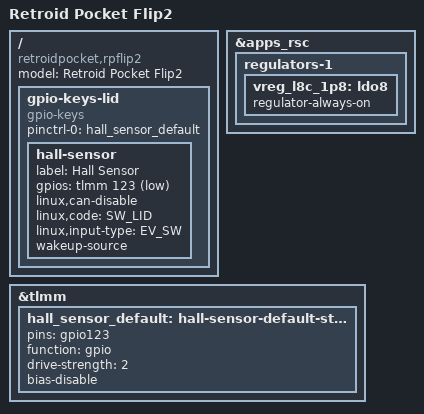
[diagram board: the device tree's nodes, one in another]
// SPDX-License-Identifier: GPL-2.0
/*
 * Copyright (c) 2025, ROCKNIX <https://rocknix.org>.
 */

/dts-v1/;

#include <dt-bindings/input/gpio-keys.h>
#include "sm8250-retroidpocket-rp5.dts"

/ {
	model = "Retroid Pocket Flip2";
	compatible = "retroidpocket,rpflip2", "qcom,sm8250";

	gpio-keys-lid {
		compatible = "gpio-keys";
		pinctrl-names = "default";
		pinctrl-0 = <&hall_sensor_default>;

		hall-sensor {
			label = "Hall Sensor";
			gpios = <&tlmm 123 GPIO_ACTIVE_LOW>;
			linux,can-disable;
			linux,code = <SW_LID>;
			linux,input-type = <EV_SW>;
			wakeup-source;
		};
	};
};

&apps_rsc {
	regulators-1 {
		vreg_l8c_1p8: ldo8 {
			regulator-always-on;
		};
	};
};


&tlmm {
	hall_sensor_default: hall-sensor-default-state {
		pins = "gpio123";
		function = "gpio";
		drive-strength = <2>;
		bias-disable;
	};
};
